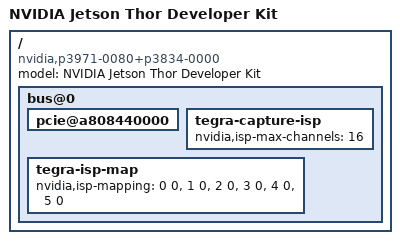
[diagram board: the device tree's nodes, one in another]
// SPDX-License-Identifier: GPL-2.0-only
// SPDX-FileCopyrightText: Copyright (c) 2024-2025, NVIDIA CORPORATION & AFFILIATES.  All rights reserved.
/dts-v1/;

#include "tegra264-p3834-0000.dtsi"
#include "tegra264-p3971-0080.dtsi"
#include "tegra264-p3971-xxxx-p3834-xxxx.dtsi"

/ {
	model = "NVIDIA Jetson Thor Developer Kit";
	compatible = "nvidia,p3971-0080+p3834-0000", "nvidia,p3834-0000", "nvidia,tegra264";

	bus@0 {
		/* C3 M.2 Key M(J1) */
		pcie@a808440000 {
                        status = "okay";
		};

		tegra-capture-isp {
			nvidia,isp-max-channels = <16>;
		};

		tegra-isp-map {
			nvidia,isp-mapping =
				<0 0>,
				<1 0>,
				<2 0>,
				<3 0>,
				<4 0>,
				<5 0>;
		};
	};
};
